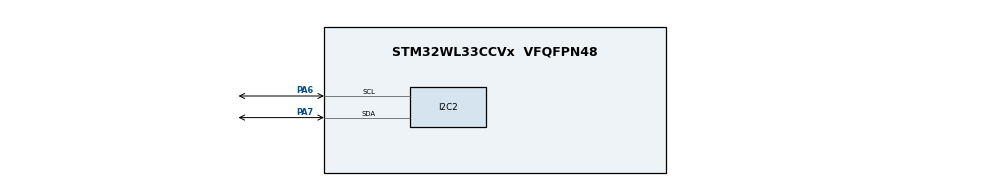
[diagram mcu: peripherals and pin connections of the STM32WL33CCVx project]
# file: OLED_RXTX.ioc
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I2C2.Timing=0x00503D58
Mcu.Family=STM32WL3
Mcu.Name=STM32WL33CCVx
Mcu.Package=VFQFPN48
NUCLEO-WL33CC1.BUTTON=1
NUCLEO-WL33CC1.BUTTON2=1
NUCLEO-WL33CC1.BUTTON3=1
NUCLEO-WL33CC1.LD1=true
NUCLEO-WL33CC1.LD2=true
NUCLEO-WL33CC1.LD3=true
NUCLEO-WL33CC1.VCP=true
PA1.Signal=USART1_TX
PA15.GPIO_Label=VCP_RX
PA15.Signal=USART1_RX
PA2.Signal=DEBUG_SWDIO
PA3.Signal=DEBUG_SWCLK
PA6.Mode=I2C
PA6.Signal=I2C2_SCL
PA7.Mode=I2C
PA7.Signal=I2C2_SDA
PB12.Signal=RCC_OSC32_OUT
PB13.Signal=RCC_OSC32_IN
ProjectManager.HeapSize=0x000
ProjectManager.StackSize=0xC00
ProjectManager.TargetToolchain=STM32CubeIDE
RCC.HSE_VALUE=48000000
RCC.HSI_VALUE=64000000
RCC.LSE_VALUE=32768
VP_NUCLEO-WL33CC1_VS_BSP_COMMON.Mode=COMMON
VP_PWR_VS_SECSignals.Mode=Security/Privilege
board=NUCLEO-WL33CC1

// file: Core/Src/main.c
/* USER CODE BEGIN Header */
/**
  ******************************************************************************
  * @file           : main.c
  * @brief          : Main program body
  ******************************************************************************
  * @attention
  *
  * Copyright (c) 2026 STMicroelectronics.
  * All rights reserved.
  *
  * This software is licensed under terms that can be found in the LICENSE file
  * in the root directory of this software component.
  * If no LICENSE file comes with this software, it is provided AS-IS.
  *
  ******************************************************************************
  */
/* USER CODE END Header */
#include "main.h"
#include "ssd1306.h"
#include "ssd1306_fonts.h"

/* USER CODE BEGIN Includes */

void RenderScreen(uint8_t *values, uint8_t count);
void DrawBarGraph(uint8_t *values, uint8_t count, uint8_t maxValue);

/* USER CODE END Includes */

/* USER CODE BEGIN PD */

#define OLED_W 128
#define OLED_H 32

// Reserve first 12 pixels for the title line (Font_7x10 + 2px padding)
#define TITLE_HEIGHT 12
#define GRAPH_TOP_Y  (TITLE_HEIGHT)
#define GRAPH_HEIGHT (OLED_H - TITLE_HEIGHT)   // 20 pixels for bars

/* USER CODE END PD */

COM_InitTypeDef BspCOMInit;

I2C_HandleTypeDef hi2c2;

void SystemClock_Config(void);
void PeriphCommonClock_Config(void);
static void MX_GPIO_Init(void);
static void MX_I2C2_Init(void);

int main(void)
{

  /* USER CODE BEGIN 1 */
  //char myText[] = "Hello OLED";
  //char retVal;
  /* USER CODE END 1 */

  /* MCU Configuration--------------------------------------------------------*/

  /* Reset of all peripherals, Initializes the Flash interface and the Systick. */
  HAL_Init();

  /* Configure the system clock */
  SystemClock_Config();

  /* Configure the peripherals common clocks */
  PeriphCommonClock_Config();

  /* Initialize all configured peripherals */
  MX_GPIO_Init();
  MX_I2C2_Init();
  /* USER CODE BEGIN 2 */
 // ssd1306_Init();
 // ssd1306_SetCursor(5,5);
 // retVal = ssd1306_WriteString(myText, Font_7x10, White);
 // ssd1306_UpdateScreen();

  ssd1306_Init();

  // Example 32 bars (fits nicely on 128px wide display)
  uint8_t graphValues[32] = {
      5,12,25,45,60,75,90,100,
      80,65,50,35,20,10,5, 8,
      15,30,50,70,85,95,70,40,
      30,25,20,15,10,5,3,0
  };

  RenderScreen(graphValues, 32);

  /* USER CODE END 2 */

  /* Initialize leds */
  BSP_LED_Init(LED_BLUE);
  BSP_LED_Init(LED_GREEN);
  BSP_LED_Init(LED_RED);

  /* Initialize USER push-button, will be used to trigger an interrupt each time it's pressed.*/
  BSP_PB_Init(B1, BUTTON_MODE_EXTI);
  BSP_PB_Init(B2, BUTTON_MODE_EXTI);
  BSP_PB_Init(B3, BUTTON_MODE_EXTI);

  /* Initialize COM1 port (115200, 8 bits (7-bit data + 1 stop bit), no parity */
  BspCOMInit.BaudRate   = 115200;
  BspCOMInit.WordLength = COM_WORDLENGTH_8B;
  BspCOMInit.StopBits   = COM_STOPBITS_1;
  BspCOMInit.Parity     = COM_PARITY_NONE;
  BspCOMInit.HwFlowCtl  = COM_HWCONTROL_NONE;
  if (BSP_COM_Init(COM1, &BspCOMInit) != BSP_ERROR_NONE)
  {
    Error_Handler();
  }

  /* Infinite loop */
  while (1)
  {

  }
}

void SystemClock_Config(void)
{
  RCC_OscInitTypeDef RCC_OscInitStruct = {0};
  RCC_ClkInitTypeDef RCC_ClkInitStruct = {0};

  /** Initializes the RCC Oscillators according to the specified parameters
  * in the RCC_OscInitTypeDef structure.
  */
  RCC_OscInitStruct.OscillatorType = RCC_OSCILLATORTYPE_HSI;
  if (HAL_RCC_OscConfig(&RCC_OscInitStruct) != HAL_OK)
  {
    Error_Handler();
  }

  /** Configure the SYSCLKSource and SYSCLKDivider
  */
  RCC_ClkInitStruct.SYSCLKSource = RCC_SYSCLKSOURCE_HSI;
  RCC_ClkInitStruct.SYSCLKDivider = RCC_RC64MPLL_DIV1;

  if (HAL_RCC_ClockConfig(&RCC_ClkInitStruct, FLASH_WAIT_STATES_1) != HAL_OK)
  {
    Error_Handler();
  }
}

void PeriphCommonClock_Config(void)
{
  RCC_PeriphCLKInitTypeDef PeriphClkInitStruct = {0};

  /** Initializes the peripherals clock
  */
  PeriphClkInitStruct.PeriphClockSelection = RCC_PERIPHCLK_SMPS;
  PeriphClkInitStruct.SmpsDivSelection = RCC_SMPSCLK_DIV2;
  PeriphClkInitStruct.KRMRateMultiplier = 2;

  if (HAL_RCCEx_PeriphCLKConfig(&PeriphClkInitStruct) != HAL_OK)
  {
    Error_Handler();
  }
}

static void MX_I2C2_Init(void)
{

  hi2c2.Instance = I2C2;
  hi2c2.Init.Timing = 0x00503D58;
  hi2c2.Init.OwnAddress1 = 0;
  hi2c2.Init.AddressingMode = I2C_ADDRESSINGMODE_7BIT;
  hi2c2.Init.DualAddressMode = I2C_DUALADDRESS_DISABLE;
  hi2c2.Init.OwnAddress2 = 0;
  hi2c2.Init.OwnAddress2Masks = I2C_OA2_NOMASK;
  hi2c2.Init.GeneralCallMode = I2C_GENERALCALL_DISABLE;
  hi2c2.Init.NoStretchMode = I2C_NOSTRETCH_DISABLE;
  if (HAL_I2C_Init(&hi2c2) != HAL_OK)
  {
    Error_Handler();
  }

  /** Configure Analogue filter
  */
  if (HAL_I2CEx_ConfigAnalogFilter(&hi2c2, I2C_ANALOGFILTER_ENABLE) != HAL_OK)
  {
    Error_Handler();
  }

  /** Configure Digital filter
  */
  if (HAL_I2CEx_ConfigDigitalFilter(&hi2c2, 0) != HAL_OK)
  {
    Error_Handler();
  }

}

static void MX_GPIO_Init(void)
{
  GPIO_InitTypeDef GPIO_InitStruct = {0};

  /* GPIO Ports Clock Enable */
  __HAL_RCC_GPIOA_CLK_ENABLE();
  __HAL_RCC_GPIOB_CLK_ENABLE();

  /*Configure GPIO pin : PA2 */
  GPIO_InitStruct.Pin = GPIO_PIN_2;
  GPIO_InitStruct.Mode = GPIO_MODE_AF_PP;
  GPIO_InitStruct.Pull = GPIO_PULLUP;
  GPIO_InitStruct.Speed = GPIO_SPEED_FREQ_LOW;
  GPIO_InitStruct.Alternate = GPIO_AF0_SWDIO;
  HAL_GPIO_Init(GPIOA, &GPIO_InitStruct);

  /*Configure GPIO pin : PA3 */
  GPIO_InitStruct.Pin = GPIO_PIN_3;
  GPIO_InitStruct.Mode = GPIO_MODE_AF_PP;
  GPIO_InitStruct.Pull = GPIO_PULLDOWN;
  GPIO_InitStruct.Speed = GPIO_SPEED_FREQ_VERY_HIGH;
  GPIO_InitStruct.Alternate = GPIO_AF0_SWCLK;
  HAL_GPIO_Init(GPIOA, &GPIO_InitStruct);

  /*Configure GPIO pin : VCP_RX_Pin */
  GPIO_InitStruct.Pin = VCP_RX_Pin;
  GPIO_InitStruct.Mode = GPIO_MODE_AF_PP;
  GPIO_InitStruct.Pull = GPIO_NOPULL;
  GPIO_InitStruct.Speed = GPIO_SPEED_FREQ_LOW;
  GPIO_InitStruct.Alternate = GPIO_AF1_USART1;
  HAL_GPIO_Init(VCP_RX_GPIO_Port, &GPIO_InitStruct);

  /**/
  HAL_PWREx_EnableGPIOPullUp(PWR_GPIO_A, PWR_GPIO_BIT_2);

  /**/
  HAL_PWREx_DisableGPIOPullUp(PWR_GPIO_A, PWR_GPIO_BIT_3|PWR_GPIO_BIT_15);

  /**/
  HAL_PWREx_DisableGPIOPullDown(PWR_GPIO_A, PWR_GPIO_BIT_3|PWR_GPIO_BIT_15);

}

/* USER CODE BEGIN 4 */

void DrawBarGraph(uint8_t *values, uint8_t count, uint8_t maxValue)
{
    uint8_t barWidth = OLED_W / count;
    if (barWidth < 1) barWidth = 1;

    for (uint8_t i = 0; i < count; i++)
    {
        uint8_t v = values[i];
        if (v > maxValue) v = maxValue;

        // scale value to graph height
        uint8_t h = (v * GRAPH_HEIGHT) / maxValue;

        uint8_t x1 = i * barWidth;
        uint8_t x2 = x1 + barWidth - 1;
        uint8_t y1 = OLED_H - 1 - h;
        uint8_t y2 = OLED_H - 1;

        if (x2 >= OLED_W) x2 = OLED_W - 1;

        // Draw filled bar using your existing function
        ssd1306_FillRectangle(x1, y1, x2, y2, White);
    }
}

void RenderScreen(uint8_t *values, uint8_t count)
{
    ssd1306_Fill(Black);

    // Draw top text
    ssd1306_SetCursor(0, 0);
    ssd1306_WriteString("Frequency: 868MHz", Font_7x10, White);

    // Bars below the text
    DrawBarGraph(values, count, 100);  // values scaled 0–100

    ssd1306_UpdateScreen();
}

/* USER CODE END 4 */

void Error_Handler(void)
{
  __disable_irq();
  while (1)
  {
  }
}
